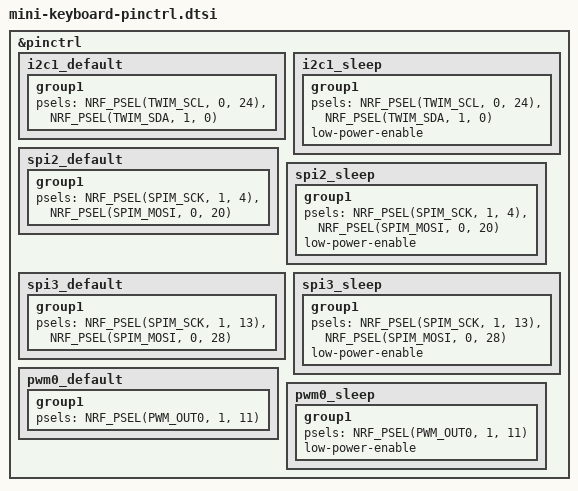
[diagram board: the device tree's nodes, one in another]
#include <zephyr/dt-bindings/pinctrl/nrf-pinctrl.h>

&pinctrl {
	i2c1_default: i2c1_default {
		group1 {
			psels = <NRF_PSEL(TWIM_SCL, 0, 24)>,
				<NRF_PSEL(TWIM_SDA, 1, 0)>;
		};
	};

	i2c1_sleep: i2c1_sleep {
		group1 {
			psels = <NRF_PSEL(TWIM_SCL, 0, 24)>,
				<NRF_PSEL(TWIM_SDA, 1, 0)>;
			low-power-enable;
		};
	};

	spi2_default: spi2_default {
		group1 {
			psels = <NRF_PSEL(SPIM_SCK, 1, 4)>,
				<NRF_PSEL(SPIM_MOSI, 0, 20)>;
		};
	};

	spi2_sleep: spi2_sleep {
		group1 {
			psels = <NRF_PSEL(SPIM_SCK, 1, 4)>,
				<NRF_PSEL(SPIM_MOSI, 0, 20)>;
			low-power-enable;
		};
	};

	spi3_default: spi3_default {
		group1 {
			psels = <NRF_PSEL(SPIM_SCK, 1, 13)>,
				<NRF_PSEL(SPIM_MOSI, 0, 28)>;
		};
	};

	spi3_sleep: spi3_sleep {
		group1 {
			psels = <NRF_PSEL(SPIM_SCK, 1, 13)>,
				<NRF_PSEL(SPIM_MOSI, 0, 28)>;
			low-power-enable;
		};
	};

	pwm0_default: pwm0_default {
		group1 {
			psels = <NRF_PSEL(PWM_OUT0, 1, 11)>;
		};
	};

	pwm0_sleep: pwm0_sleep {
		group1 {
			psels = <NRF_PSEL(PWM_OUT0, 1, 11)>;
			low-power-enable;
		};
	};
};
